# CY8C5888LTI_LP097 register map
File version: 0.1
Registers are 8-bit, read-write, no defined reset value unless marked. A register's access mark holds for its fields unless they carry their own. Offsets are from the block's base; [hi:lo] are bit positions; 'fields as' and 'values as' point back to an identical list.

## PWM1
Base 0x00000000
0x4000642C PWM1_COMPARE_Reg 16-bit — UDB.D0 - Assigned Compare Value
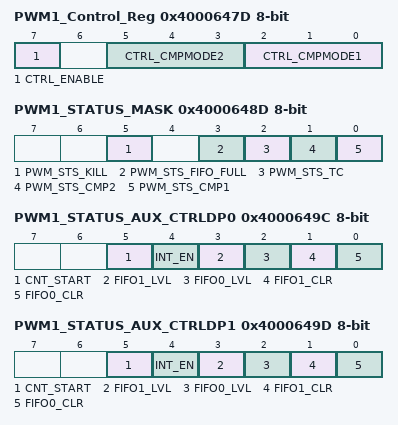
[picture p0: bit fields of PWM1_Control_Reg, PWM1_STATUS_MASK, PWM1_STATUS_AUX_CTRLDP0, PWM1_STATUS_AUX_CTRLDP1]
0x4000647D PWM1_Control_Reg — UDB Control Register - Assigned Control Register Value
  [7] CTRL_ENABLE — Enable the PWM
  [5:3] CTRL_CMPMODE2 — Compare mode 2
  [2:0] CTRL_CMPMODE1 — Compare mode 1
0x4000648D PWM1_STATUS_MASK — UDB Status bits Interrupt Mask Enable Register
  [5] PWM_STS_KILL ro — Enables the Interrupt on Kill
  [3] PWM_STS_FIFO_FULL ro — FIFO Full Status Mask
  [2] PWM_STS_TC ro — Enables the Interrupt on Terminal Count
  [1] PWM_STS_CMP2 ro — Enables the Interrupt on Compare 2
  [0] PWM_STS_CMP1 ro — Enables the Interrupt on Compare 1
0x4000649C PWM1_STATUS_AUX_CTRLDP0 — UDB Auxilliary Control Register
  [5] CNT_START — FIFO0 clear
    0=E_CNT_START0 (Disable counter); 1=E_CNT_START1 (Enable counter)
  [4] INT_EN
    0=E_INT_EN0 (Interrupt disabled); 1=E_INT_EN1 (Interrupt enabled)
  [3] FIFO1_LVL — FIFO level
    0=E_FIFO_LVL_0 (FIFO LVL: input mode: FIFO not full; output mode: FIFO not empty); 1=E_FIFO_LVL_1 (FIFO LVL: input mode: FIFO at least 1/2 empty; output mode: FIFO at least 1/2 full)
  [2] FIFO0_LVL — FIFO level
    values as FIFO1_LVL
  [1] FIFO1_CLR — FIFO1 clear
    0=E_FIFO_CLR_0 (Normal FIFO operation); 1=E_FIFO_CLR_1 (Clear FIFO state)
  [0] FIFO0_CLR — FIFO0 clear
    values as FIFO1_CLR
0x4000649D PWM1_STATUS_AUX_CTRLDP1 — UDB Auxilliary Control Register
  fields as PWM1_STATUS_AUX_CTRLDP0

## PWM5
Base 0x00000000
0x40006424 PWM5_COMPARE_Reg 16-bit — UDB.D0 - Assigned Compare Value
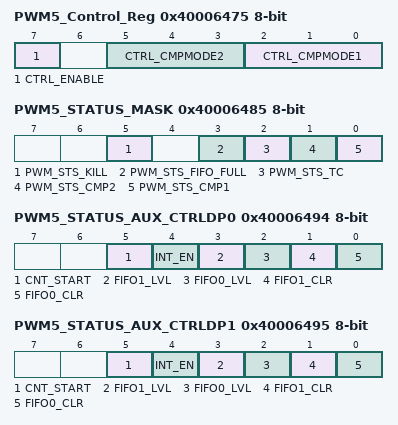
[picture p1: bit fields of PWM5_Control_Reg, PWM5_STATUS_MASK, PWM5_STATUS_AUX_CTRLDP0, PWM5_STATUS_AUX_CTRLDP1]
0x40006475 PWM5_Control_Reg — UDB Control Register - Assigned Control Register Value
  [7] CTRL_ENABLE — Enable the PWM
  [5:3] CTRL_CMPMODE2 — Compare mode 2
  [2:0] CTRL_CMPMODE1 — Compare mode 1
0x40006485 PWM5_STATUS_MASK — UDB Status bits Interrupt Mask Enable Register
  [5] PWM_STS_KILL ro — Enables the Interrupt on Kill
  [3] PWM_STS_FIFO_FULL ro — FIFO Full Status Mask
  [2] PWM_STS_TC ro — Enables the Interrupt on Terminal Count
  [1] PWM_STS_CMP2 ro — Enables the Interrupt on Compare 2
  [0] PWM_STS_CMP1 ro — Enables the Interrupt on Compare 1
0x40006494 PWM5_STATUS_AUX_CTRLDP0 — UDB Auxilliary Control Register
  [5] CNT_START — FIFO0 clear
    0=E_CNT_START0 (Disable counter); 1=E_CNT_START1 (Enable counter)
  [4] INT_EN
    0=E_INT_EN0 (Interrupt disabled); 1=E_INT_EN1 (Interrupt enabled)
  [3] FIFO1_LVL — FIFO level
    0=E_FIFO_LVL_0 (FIFO LVL: input mode: FIFO not full; output mode: FIFO not empty); 1=E_FIFO_LVL_1 (FIFO LVL: input mode: FIFO at least 1/2 empty; output mode: FIFO at least 1/2 full)
  [2] FIFO0_LVL — FIFO level
    values as FIFO1_LVL
  [1] FIFO1_CLR — FIFO1 clear
    0=E_FIFO_CLR_0 (Normal FIFO operation); 1=E_FIFO_CLR_1 (Clear FIFO state)
  [0] FIFO0_CLR — FIFO0 clear
    values as FIFO1_CLR
0x40006495 PWM5_STATUS_AUX_CTRLDP1 — UDB Auxilliary Control Register
  fields as PWM5_STATUS_AUX_CTRLDP0

## PWM3
Base 0x00000000
0x4000642E PWM3_COMPARE_Reg 16-bit — UDB.D0 - Assigned Compare Value
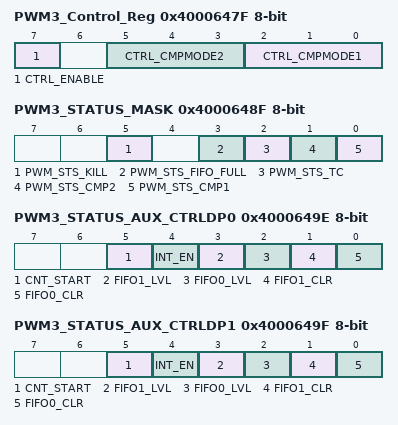
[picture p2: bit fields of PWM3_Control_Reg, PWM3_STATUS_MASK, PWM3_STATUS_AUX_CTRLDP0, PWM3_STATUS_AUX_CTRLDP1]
0x4000647F PWM3_Control_Reg — UDB Control Register - Assigned Control Register Value
  [7] CTRL_ENABLE — Enable the PWM
  [5:3] CTRL_CMPMODE2 — Compare mode 2
  [2:0] CTRL_CMPMODE1 — Compare mode 1
0x4000648F PWM3_STATUS_MASK — UDB Status bits Interrupt Mask Enable Register
  [5] PWM_STS_KILL ro — Enables the Interrupt on Kill
  [3] PWM_STS_FIFO_FULL ro — FIFO Full Status Mask
  [2] PWM_STS_TC ro — Enables the Interrupt on Terminal Count
  [1] PWM_STS_CMP2 ro — Enables the Interrupt on Compare 2
  [0] PWM_STS_CMP1 ro — Enables the Interrupt on Compare 1
0x4000649E PWM3_STATUS_AUX_CTRLDP0 — UDB Auxilliary Control Register
  [5] CNT_START — FIFO0 clear
    0=E_CNT_START0 (Disable counter); 1=E_CNT_START1 (Enable counter)
  [4] INT_EN
    0=E_INT_EN0 (Interrupt disabled); 1=E_INT_EN1 (Interrupt enabled)
  [3] FIFO1_LVL — FIFO level
    0=E_FIFO_LVL_0 (FIFO LVL: input mode: FIFO not full; output mode: FIFO not empty); 1=E_FIFO_LVL_1 (FIFO LVL: input mode: FIFO at least 1/2 empty; output mode: FIFO at least 1/2 full)
  [2] FIFO0_LVL — FIFO level
    values as FIFO1_LVL
  [1] FIFO1_CLR — FIFO1 clear
    0=E_FIFO_CLR_0 (Normal FIFO operation); 1=E_FIFO_CLR_1 (Clear FIFO state)
  [0] FIFO0_CLR — FIFO0 clear
    values as FIFO1_CLR
0x4000649F PWM3_STATUS_AUX_CTRLDP1 — UDB Auxilliary Control Register
  fields as PWM3_STATUS_AUX_CTRLDP0

## PWM6
Base 0x00000000
0x40006428 PWM6_COMPARE_Reg 16-bit — UDB.D0 - Assigned Compare Value
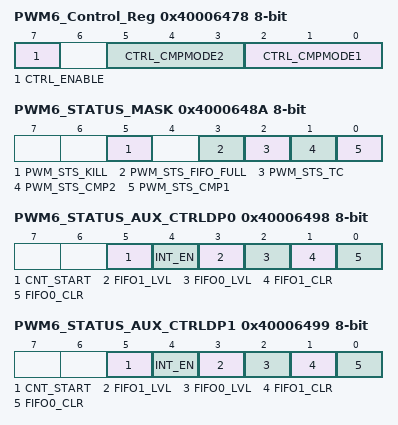
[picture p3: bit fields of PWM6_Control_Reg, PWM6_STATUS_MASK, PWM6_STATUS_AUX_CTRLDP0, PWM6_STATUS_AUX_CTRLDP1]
0x40006478 PWM6_Control_Reg — UDB Control Register - Assigned Control Register Value
  [7] CTRL_ENABLE — Enable the PWM
  [5:3] CTRL_CMPMODE2 — Compare mode 2
  [2:0] CTRL_CMPMODE1 — Compare mode 1
0x4000648A PWM6_STATUS_MASK — UDB Status bits Interrupt Mask Enable Register
  [5] PWM_STS_KILL ro — Enables the Interrupt on Kill
  [3] PWM_STS_FIFO_FULL ro — FIFO Full Status Mask
  [2] PWM_STS_TC ro — Enables the Interrupt on Terminal Count
  [1] PWM_STS_CMP2 ro — Enables the Interrupt on Compare 2
  [0] PWM_STS_CMP1 ro — Enables the Interrupt on Compare 1
0x40006498 PWM6_STATUS_AUX_CTRLDP0 — UDB Auxilliary Control Register
  [5] CNT_START — FIFO0 clear
    0=E_CNT_START0 (Disable counter); 1=E_CNT_START1 (Enable counter)
  [4] INT_EN
    0=E_INT_EN0 (Interrupt disabled); 1=E_INT_EN1 (Interrupt enabled)
  [3] FIFO1_LVL — FIFO level
    0=E_FIFO_LVL_0 (FIFO LVL: input mode: FIFO not full; output mode: FIFO not empty); 1=E_FIFO_LVL_1 (FIFO LVL: input mode: FIFO at least 1/2 empty; output mode: FIFO at least 1/2 full)
  [2] FIFO0_LVL — FIFO level
    values as FIFO1_LVL
  [1] FIFO1_CLR — FIFO1 clear
    0=E_FIFO_CLR_0 (Normal FIFO operation); 1=E_FIFO_CLR_1 (Clear FIFO state)
  [0] FIFO0_CLR — FIFO0 clear
    values as FIFO1_CLR
0x40006499 PWM6_STATUS_AUX_CTRLDP1 — UDB Auxilliary Control Register
  fields as PWM6_STATUS_AUX_CTRLDP0
